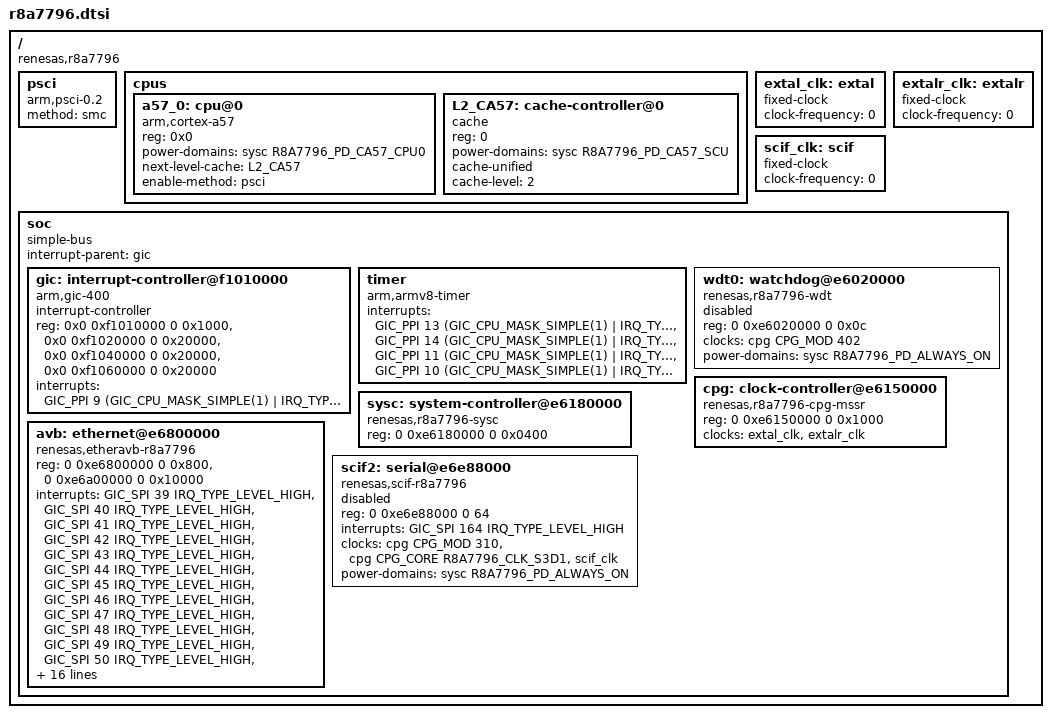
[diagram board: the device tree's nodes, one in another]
/*
 * Device Tree Source for the r8a7796 SoC
 *
 * Copyright (C) 2016 Renesas Electronics Corp.
 *
 * This file is licensed under the terms of the GNU General Public License
 * version 2.  This program is licensed "as is" without any warranty of any
 * kind, whether express or implied.
 */

#include <dt-bindings/clock/r8a7796-cpg-mssr.h>
#include <dt-bindings/interrupt-controller/arm-gic.h>
#include <dt-bindings/power/r8a7796-sysc.h>

/ {
	compatible = "renesas,r8a7796";
	#address-cells = <2>;
	#size-cells = <2>;

	psci {
		compatible = "arm,psci-0.2";
		method = "smc";
	};

	cpus {
		#address-cells = <1>;
		#size-cells = <0>;

		/* 1 core only at this point */
		a57_0: cpu@0 {
			compatible = "arm,cortex-a57", "arm,armv8";
			reg = <0x0>;
			device_type = "cpu";
			power-domains = <&sysc R8A7796_PD_CA57_CPU0>;
			next-level-cache = <&L2_CA57>;
			enable-method = "psci";
		};

		L2_CA57: cache-controller@0 {
			compatible = "cache";
			reg = <0>;
			power-domains = <&sysc R8A7796_PD_CA57_SCU>;
			cache-unified;
			cache-level = <2>;
		};
	};

	extal_clk: extal {
		compatible = "fixed-clock";
		#clock-cells = <0>;
		/* This value must be overridden by the board */
		clock-frequency = <0>;
	};

	extalr_clk: extalr {
		compatible = "fixed-clock";
		#clock-cells = <0>;
		/* This value must be overridden by the board */
		clock-frequency = <0>;
	};

	/* External SCIF clock - to be overridden by boards that provide it */
	scif_clk: scif {
		compatible = "fixed-clock";
		#clock-cells = <0>;
		clock-frequency = <0>;
	};

	soc {
		compatible = "simple-bus";
		interrupt-parent = <&gic>;
		#address-cells = <2>;
		#size-cells = <2>;
		ranges;

		gic: interrupt-controller@f1010000 {
			compatible = "arm,gic-400";
			#interrupt-cells = <3>;
			#address-cells = <0>;
			interrupt-controller;
			reg = <0x0 0xf1010000 0 0x1000>,
			      <0x0 0xf1020000 0 0x20000>,
			      <0x0 0xf1040000 0 0x20000>,
			      <0x0 0xf1060000 0 0x20000>;
			interrupts = <GIC_PPI 9
					(GIC_CPU_MASK_SIMPLE(1) | IRQ_TYPE_LEVEL_HIGH)>;
		};

		timer {
			compatible = "arm,armv8-timer";
			interrupts = <GIC_PPI 13
					(GIC_CPU_MASK_SIMPLE(1) | IRQ_TYPE_LEVEL_LOW)>,
				     <GIC_PPI 14
					(GIC_CPU_MASK_SIMPLE(1) | IRQ_TYPE_LEVEL_LOW)>,
				     <GIC_PPI 11
					(GIC_CPU_MASK_SIMPLE(1) | IRQ_TYPE_LEVEL_LOW)>,
				     <GIC_PPI 10
					(GIC_CPU_MASK_SIMPLE(1) | IRQ_TYPE_LEVEL_LOW)>;
		};

		wdt0: watchdog@e6020000 {
			compatible = "renesas,r8a7796-wdt",
				     "renesas,rcar-gen3-wdt";
			reg = <0 0xe6020000 0 0x0c>;
			clocks = <&cpg CPG_MOD 402>;
			power-domains = <&sysc R8A7796_PD_ALWAYS_ON>;
			status = "disabled";
		};

		cpg: clock-controller@e6150000 {
			compatible = "renesas,r8a7796-cpg-mssr";
			reg = <0 0xe6150000 0 0x1000>;
			clocks = <&extal_clk>, <&extalr_clk>;
			clock-names = "extal", "extalr";
			#clock-cells = <2>;
			#power-domain-cells = <0>;
		};

		sysc: system-controller@e6180000 {
			compatible = "renesas,r8a7796-sysc";
			reg = <0 0xe6180000 0 0x0400>;
			#power-domain-cells = <1>;
		};

		avb: ethernet@e6800000 {
			compatible = "renesas,etheravb-r8a7796",
				     "renesas,etheravb-rcar-gen3";
			reg = <0 0xe6800000 0 0x800>, <0 0xe6a00000 0 0x10000>;
			interrupts = <GIC_SPI 39 IRQ_TYPE_LEVEL_HIGH>,
				     <GIC_SPI 40 IRQ_TYPE_LEVEL_HIGH>,
				     <GIC_SPI 41 IRQ_TYPE_LEVEL_HIGH>,
				     <GIC_SPI 42 IRQ_TYPE_LEVEL_HIGH>,
				     <GIC_SPI 43 IRQ_TYPE_LEVEL_HIGH>,
				     <GIC_SPI 44 IRQ_TYPE_LEVEL_HIGH>,
				     <GIC_SPI 45 IRQ_TYPE_LEVEL_HIGH>,
				     <GIC_SPI 46 IRQ_TYPE_LEVEL_HIGH>,
				     <GIC_SPI 47 IRQ_TYPE_LEVEL_HIGH>,
				     <GIC_SPI 48 IRQ_TYPE_LEVEL_HIGH>,
				     <GIC_SPI 49 IRQ_TYPE_LEVEL_HIGH>,
				     <GIC_SPI 50 IRQ_TYPE_LEVEL_HIGH>,
				     <GIC_SPI 51 IRQ_TYPE_LEVEL_HIGH>,
				     <GIC_SPI 52 IRQ_TYPE_LEVEL_HIGH>,
				     <GIC_SPI 53 IRQ_TYPE_LEVEL_HIGH>,
				     <GIC_SPI 54 IRQ_TYPE_LEVEL_HIGH>,
				     <GIC_SPI 55 IRQ_TYPE_LEVEL_HIGH>,
				     <GIC_SPI 56 IRQ_TYPE_LEVEL_HIGH>,
				     <GIC_SPI 57 IRQ_TYPE_LEVEL_HIGH>,
				     <GIC_SPI 58 IRQ_TYPE_LEVEL_HIGH>,
				     <GIC_SPI 59 IRQ_TYPE_LEVEL_HIGH>,
				     <GIC_SPI 60 IRQ_TYPE_LEVEL_HIGH>,
				     <GIC_SPI 61 IRQ_TYPE_LEVEL_HIGH>,
				     <GIC_SPI 62 IRQ_TYPE_LEVEL_HIGH>,
				     <GIC_SPI 63 IRQ_TYPE_LEVEL_HIGH>;
			interrupt-names = "ch0", "ch1", "ch2", "ch3",
					  "ch4", "ch5", "ch6", "ch7",
					  "ch8", "ch9", "ch10", "ch11",
					  "ch12", "ch13", "ch14", "ch15",
					  "ch16", "ch17", "ch18", "ch19",
					  "ch20", "ch21", "ch22", "ch23",
					  "ch24";
			clocks = <&cpg CPG_MOD 812>;
			power-domains = <&sysc R8A7796_PD_ALWAYS_ON>;
			phy-mode = "rgmii-id";
			#address-cells = <1>;
			#size-cells = <0>;
		};

		scif2: serial@e6e88000 {
			compatible = "renesas,scif-r8a7796",
				     "renesas,rcar-gen3-scif", "renesas,scif";
			reg = <0 0xe6e88000 0 64>;
			interrupts = <GIC_SPI 164 IRQ_TYPE_LEVEL_HIGH>;
			clocks = <&cpg CPG_MOD 310>,
				 <&cpg CPG_CORE R8A7796_CLK_S3D1>,
				 <&scif_clk>;
			clock-names = "fck", "brg_int", "scif_clk";
			power-domains = <&sysc R8A7796_PD_ALWAYS_ON>;
			status = "disabled";
		};
	};
};
